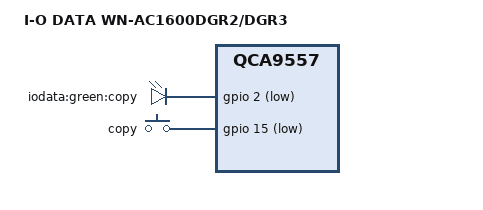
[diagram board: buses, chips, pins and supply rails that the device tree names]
// SPDX-License-Identifier: GPL-2.0-or-later OR MIT

#include "qca9557_iodata_wn-ac-dgr.dtsi"

/ {
	compatible = "iodata,wn-ac1600dgr2", "iodata,wn-ac1600dgr3", "qca,qca9557";
	model = "I-O DATA WN-AC1600DGR2/DGR3";
};

&leds {
	copy {
		label = "iodata:green:copy";
		gpios = <&gpio 2 GPIO_ACTIVE_LOW>;
	};
};

&keys {
	copy {
		label = "copy";
		gpios = <&gpio 15 GPIO_ACTIVE_LOW>;
		linux,code = <BTN_1>;
		debounce-interval = <60>;
	};
};
